# MIMXRT1062 register map
Vendor: nxp.com; File version: 1.0
CPU: CM7 r0p1, little endian, MPU, FPU, VTOR, 4 interrupt priority bits
Registers are 32-bit, read-write, reset 0x0 unless marked. A register's access mark holds for its fields unless they carry their own. Offsets are from the block's base; [hi:lo] are bit positions; {n}, {i} and the like mark numbered series; 'fields as' and 'values as' point back to an identical list.

## PMU
Base 0x400D8000; register names take the prefix PMU_; alternate view of CCM_ANALOG
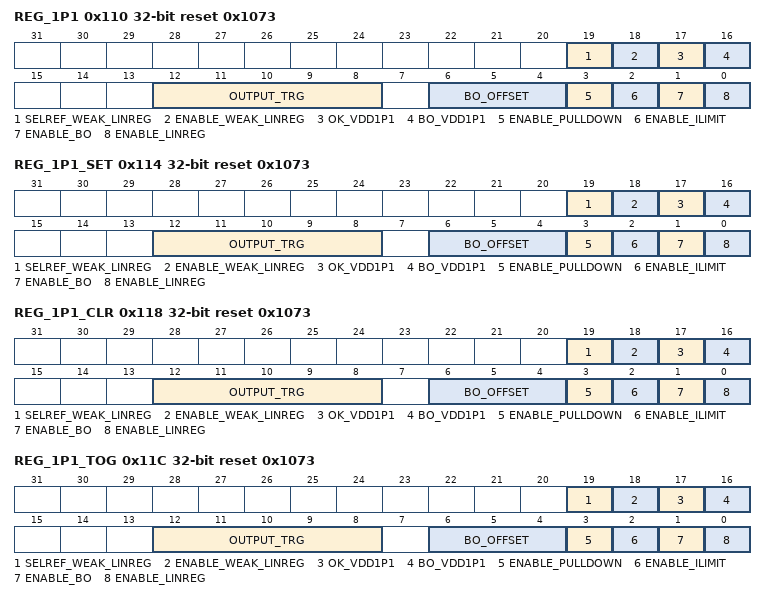
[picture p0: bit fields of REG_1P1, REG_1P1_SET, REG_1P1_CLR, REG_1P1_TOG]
0x110 REG_1P1 reset 0x1073 — Regulator 1P1 Register
  [19] SELREF_WEAK_LINREG — Selects the source for the reference voltage of the weak 1p1 regulator.
    0=Weak-linreg output tracks low-power-bandgap voltage; 1=Weak-linreg output tracks VDD_SOC_IN voltage
  [18] ENABLE_WEAK_LINREG — Enables the weak 1p1 regulator
  [17] OK_VDD1P1 ro — Status bit that signals when the regulator output is ok. 1 = regulator output > brownout target
  [16] BO_VDD1P1 ro — Status bit that signals when a brownout is detected on the regulator output.
  [12:8] OUTPUT_TRG — Control bits to adjust the regulator output voltage
    4=0.8V; 16=1.1V
  [6:4] BO_OFFSET — Control bits to adjust the regulator brownout offset voltage in 25mV steps
  [3] ENABLE_PULLDOWN — Control bit to enable the pull-down circuitry in the regulator
  [2] ENABLE_ILIMIT — Control bit to enable the current-limit circuitry in the regulator.
  [1] ENABLE_BO — Control bit to enable the brownout circuitry in the regulator.
  [0] ENABLE_LINREG — Control bit to enable the regulator output.
0x114 REG_1P1_SET reset 0x1073 — Regulator 1P1 Register
  fields as REG_1P1
0x118 REG_1P1_CLR reset 0x1073 — Regulator 1P1 Register
  fields as REG_1P1
0x11C REG_1P1_TOG reset 0x1073 — Regulator 1P1 Register
  fields as REG_1P1
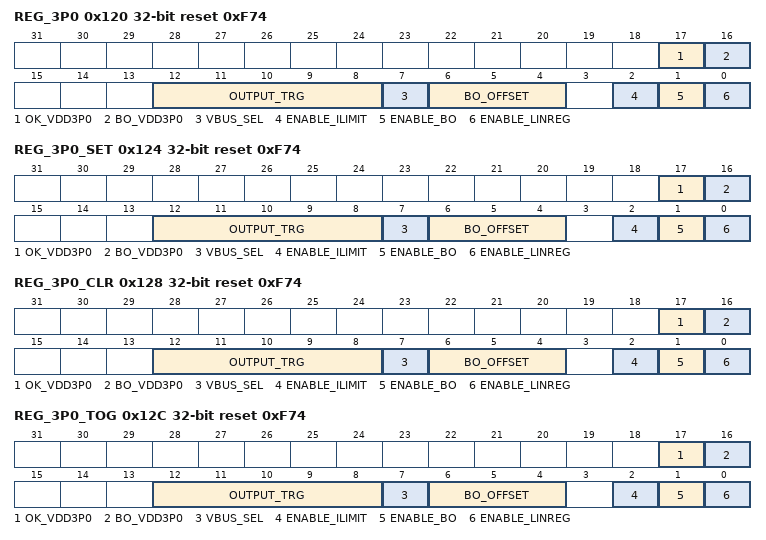
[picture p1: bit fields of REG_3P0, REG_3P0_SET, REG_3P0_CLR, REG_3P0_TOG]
0x120 REG_3P0 reset 0xF74 — Regulator 3P0 Register
  [17] OK_VDD3P0 ro — Status bit that signals when the regulator output is ok. 1 = regulator output > brownout target
  [16] BO_VDD3P0 ro — Status bit that signals when a brownout is detected on the regulator output.
  [12:8] OUTPUT_TRG — Control bits to adjust the regulator output voltage
    0=2.625V; 15=3.000V; 31=3.400V
  [7] VBUS_SEL — Select input voltage source for LDO_3P0 from either USB_OTG1_VBUS or USB_OTG2_VBUS
    0=USB_OTG2_VBUS (Utilize VBUS OTG2 power); 1=USB_OTG1_VBUS (Utilize VBUS OTG1 power)
  [6:4] BO_OFFSET — Control bits to adjust the regulator brownout offset voltage in 25mV steps
  [2] ENABLE_ILIMIT — Control bit to enable the current-limit circuitry in the regulator.
  [1] ENABLE_BO — Control bit to enable the brownout circuitry in the regulator.
  [0] ENABLE_LINREG — Control bit to enable the regulator output to be set by the programmed target voltage setting and internal bandgap reference
0x124 REG_3P0_SET reset 0xF74 — Regulator 3P0 Register
  fields as REG_3P0
0x128 REG_3P0_CLR reset 0xF74 — Regulator 3P0 Register
  fields as REG_3P0
0x12C REG_3P0_TOG reset 0xF74 — Regulator 3P0 Register
  fields as REG_3P0
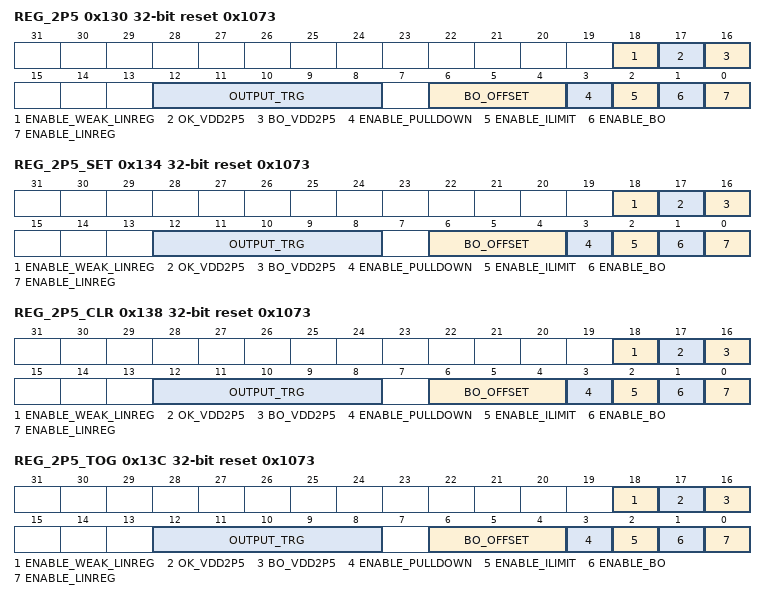
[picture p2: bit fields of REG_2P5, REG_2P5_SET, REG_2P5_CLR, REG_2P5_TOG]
0x130 REG_2P5 reset 0x1073 — Regulator 2P5 Register
  [18] ENABLE_WEAK_LINREG — Enables the weak 2p5 regulator
  [17] OK_VDD2P5 ro — Status bit that signals when the regulator output is ok. 1 = regulator output > brownout target
  [16] BO_VDD2P5 ro — Status bit that signals when a brownout is detected on the regulator output.
  [12:8] OUTPUT_TRG — Control bits to adjust the regulator output voltage
    0=2.10V; 16=2.50V; 31=2.875V
  [6:4] BO_OFFSET — Control bits to adjust the regulator brownout offset voltage in 25mV steps
  [3] ENABLE_PULLDOWN — Control bit to enable the pull-down circuitry in the regulator
  [2] ENABLE_ILIMIT — Control bit to enable the current-limit circuitry in the regulator.
  [1] ENABLE_BO — Control bit to enable the brownout circuitry in the regulator.
  [0] ENABLE_LINREG — Control bit to enable the regulator output.
0x134 REG_2P5_SET reset 0x1073 — Regulator 2P5 Register
  fields as REG_2P5
0x138 REG_2P5_CLR reset 0x1073 — Regulator 2P5 Register
  fields as REG_2P5
0x13C REG_2P5_TOG reset 0x1073 — Regulator 2P5 Register
  fields as REG_2P5
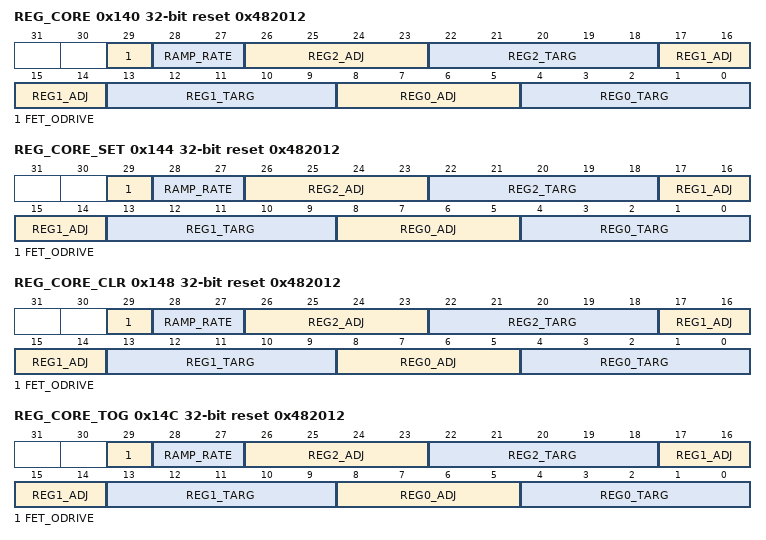
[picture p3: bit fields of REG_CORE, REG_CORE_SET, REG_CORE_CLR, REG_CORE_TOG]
0x140 REG_CORE reset 0x482012 — Digital Regulator Core Register
  [29] FET_ODRIVE — If set, increases the gate drive on power gating FETs to reduce leakage in the off state
  [28:27] RAMP_RATE — Regulator voltage ramp rate.
    0=Fast; 1=Medium Fast; 2=Medium Slow; 3=Slow
  [26:23] REG2_ADJ — This bit field defines the adjustment bits to calibrate the target value of Reg2. The adjustment is applied on top on any adjustment applied to the global reference in the misc0 register.
    0=No adjustment; 1=+ 0.25%; 2=+ 0.50%; 3=+ 0.75%; 4=+ 1.00%; 5=+ 1.25%; 6=+ 1.50%; 7=+ 1.75%; 8=- 0.25%; 9=- 0.50%; 10=- 0.75%; 11=- 1.00%; 12=- 1.25%; 13=- 1.50%; 14=- 1.75%; 15=- 2.00%
  [22:18] REG2_TARG — This field defines the target voltage for the SOC power domain
    0=Power gated off; 1=Target core voltage = 0.725V; 2=Target core voltage = 0.750V; 3=Target core voltage = 0.775V; 16=Target core voltage = 1.100V; 30=Target core voltage = 1.450V; 31=Power FET switched full on. No regulation.
  [17:14] REG1_ADJ — This bit field defines the adjustment bits to calibrate the target value of Reg1. The adjustment is applied on top on any adjustment applied to the global reference in the misc0 register.
    values as REG2_ADJ
  [13:9] REG1_TARG — This bit field defines the target voltage for the vpu/gpu power domain. Single bit increments reflect 25mV core voltage steps. Not all steps will make sense to use either because of input supply limitations or load operation.
    values as REG2_TARG
  [8:5] REG0_ADJ — This bit field defines the adjustment bits to calibrate the target value of Reg0. The adjustment is applied on top on any adjustment applied to the global reference in the misc0 register.
    values as REG2_ADJ
  [4:0] REG0_TARG — This field defines the target voltage for the Arm core power domain
    values as REG2_TARG
0x144 REG_CORE_SET reset 0x482012 — Digital Regulator Core Register
  fields as REG_CORE
0x148 REG_CORE_CLR reset 0x482012 — Digital Regulator Core Register
  fields as REG_CORE
0x14C REG_CORE_TOG reset 0x482012 — Digital Regulator Core Register
  fields as REG_CORE
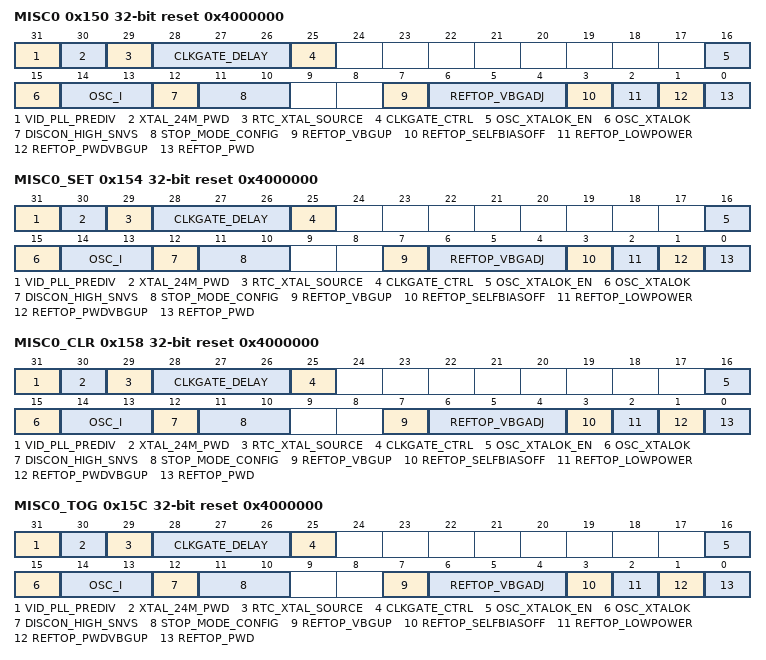
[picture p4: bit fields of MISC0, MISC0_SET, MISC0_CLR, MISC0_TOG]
0x150 MISC0 reset 0x4000000 — Miscellaneous Register 0
  [31] VID_PLL_PREDIV — Predivider for the source clock of the PLL's.
    0=Divide by 1; 1=Divide by 2
  [30] XTAL_24M_PWD — This field powers down the 24M crystal oscillator if set true.
  [29] RTC_XTAL_SOURCE ro — This field indicates which chip source is being used for the rtc clock.
    0=Internal ring oscillator; 1=RTC_XTAL
  [28:26] CLKGATE_DELAY — This field specifies the delay between powering up the XTAL 24MHz clock and releasing the clock to the digital logic inside the analog block
    0=0.5ms; 1=1.0ms; 2=2.0ms; 3=3.0ms; 4=4.0ms; 5=5.0ms; 6=6.0ms; 7=7.0ms
  [25] CLKGATE_CTRL — This bit allows disabling the clock gate (always ungated) for the xtal 24MHz clock that clocks the digital logic in the analog block
    0=ALLOW_AUTO_GATE (Allow the logic to automatically gate the clock when the XTAL is powered down.); 1=NO_AUTO_GATE (Prevent the logic from ever gating off the clock.)
  [16] OSC_XTALOK_EN — This bit enables the detector that signals when the 24MHz crystal oscillator is stable
  [15] OSC_XTALOK ro — Status bit that signals that the output of the 24-MHz crystal oscillator is stable
  [14:13] OSC_I — This field determines the bias current in the 24MHz oscillator
    0=NOMINAL; 1=MINUS_12_5_PERCENT (Decrease current by 12.5%); 2=MINUS_25_PERCENT (Decrease current by 25.0%); 3=MINUS_37_5_PERCENT (Decrease current by 37.5%)
  [12] DISCON_HIGH_SNVS — This bit controls a switch from VDD_HIGH_IN to VDD_SNVS_IN.
    0=Turn on the switch; 1=Turn off the switch
  [11:10] STOP_MODE_CONFIG — Configure the analog behavior in stop mode.
    0=SUSPEND (DSM); 1=STANDBY (Analog regulators are ON.); 2=STOP (lower power); 3=STOP (very lower power)
  [7] REFTOP_VBGUP — Status bit that signals the analog bandgap voltage is up and stable. 1 - Stable.
  [6:4] REFTOP_VBGADJ
    0=Nominal VBG; 1=VBG+0.78%; 2=VBG+1.56%; 3=VBG+2.34%; 4=VBG-0.78%; 5=VBG-1.56%; 6=VBG-2.34%; 7=VBG-3.12%
  [3] REFTOP_SELFBIASOFF — Control bit to disable the self-bias circuit in the analog bandgap
    0=Uses coarse bias currents for startup; 1=Uses bandgap-based bias currents for best performance
  [2] REFTOP_LOWPOWER — Control bit to enable the low-power mode in the analog bandgap.
  [1] REFTOP_PWDVBGUP — Control bit to power down the VBG-up detection circuitry in the analog bandgap.
  [0] REFTOP_PWD — Control bit to power-down the analog bandgap reference circuitry
0x154 MISC0_SET reset 0x4000000 — Miscellaneous Register 0
  fields as MISC0
0x158 MISC0_CLR reset 0x4000000 — Miscellaneous Register 0
  fields as MISC0
0x15C MISC0_TOG reset 0x4000000 — Miscellaneous Register 0
  fields as MISC0
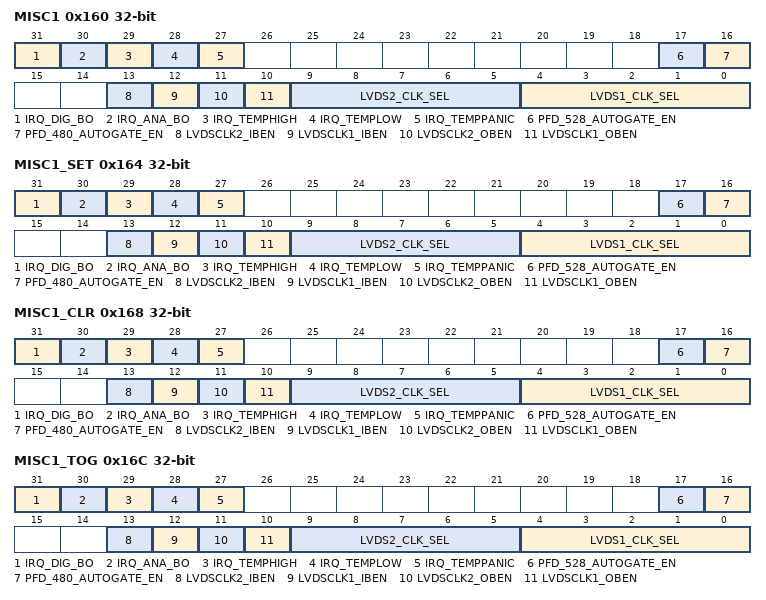
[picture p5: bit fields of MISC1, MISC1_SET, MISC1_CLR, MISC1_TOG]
0x160 MISC1 — Miscellaneous Register 1
  [31] IRQ_DIG_BO write-1-clears — This status bit is set to one when when any of the digital regulator brownout interrupts assert
  [30] IRQ_ANA_BO write-1-clears — This status bit is set to one when when any of the analog regulator brownout interrupts assert
  [29] IRQ_TEMPHIGH write-1-clears — This status bit is set to one when the temperature sensor high interrupt asserts for high temperature
  [28] IRQ_TEMPLOW write-1-clears — This status bit is set to one when the temperature sensor low interrupt asserts for low temperature
  [27] IRQ_TEMPPANIC write-1-clears — This status bit is set to one when the temperature sensor panic interrupt asserts for a panic high temperature
  [17] PFD_528_AUTOGATE_EN — This enables a feature that will clkgate (reset) all PFD_528 clocks anytime the PLL_528 is unlocked or powered off
  [16] PFD_480_AUTOGATE_EN — This enables a feature that will clkgate (reset) all PFD_480 clocks anytime the USB1_PLL_480 is unlocked or powered off
  [13] LVDSCLK2_IBEN — This enables the LVDS input buffer for anaclk2/2b
  [12] LVDSCLK1_IBEN — This enables the LVDS input buffer for anaclk1/1b
  [11] LVDSCLK2_OBEN — This enables the LVDS output buffer for anaclk2/2b
  [10] LVDSCLK1_OBEN — This enables the LVDS output buffer for anaclk1/1b
  [9:5] LVDS2_CLK_SEL — This field selects the clk to be routed to anaclk2/2b.Not related to PMU.
    0=ARM_PLL; 1=SYS_PLL (System PLL); {v}=PFD{v+2} (ref_pfd{v+2}_clk == pll2_pfd{v-2}_clk) (v=2..5); 6=AUDIO_PLL; 7=VIDEO_PLL; 8=MLB_PLL; 9=ETHERNET_REF (ethernet ref clock (ENET_PLL)); 10=PCIE_REF (PCIe ref clock (125M)); 11=SATA_REF (SATA ref clock (100M)); 12=USB1_PLL (USB1 PLL clock); 13=USB2_PLL (USB2 PLL clock); {v}=PFD{v-14} (ref_pfd{v-14}_clk == pll3_pfd{v-14}_clk) (v=14..17); 18=XTAL (xtal (24M)); 19=LVDS1 (LVDS1 (loopback)); 20=LVDS2 (LVDS2 (not useful))
  [4:0] LVDS1_CLK_SEL — This field selects the clk to be routed to anaclk1/1b.Not related to PMU.
    0=ARM_PLL; 1=SYS_PLL (System PLL); {v}=PFD{v+2} (ref_pfd{v+2}_clk == pll2_pfd{v-2}_clk) (v=2..5); 6=AUDIO_PLL; 7=VIDEO_PLL; 9=ETHERNET_REF (ethernet ref clock (ENET_PLL)); 12=USB1_PLL (USB1 PLL clock); 13=USB2_PLL (USB2 PLL clock); {v}=PFD{v-14} (ref_pfd{v-14}_clk == pll3_pfd{v-14}_clk) (v=14..17); 18=XTAL (xtal (24M))
0x164 MISC1_SET — Miscellaneous Register 1
  fields as MISC1
0x168 MISC1_CLR — Miscellaneous Register 1
  fields as MISC1
0x16C MISC1_TOG — Miscellaneous Register 1
  fields as MISC1
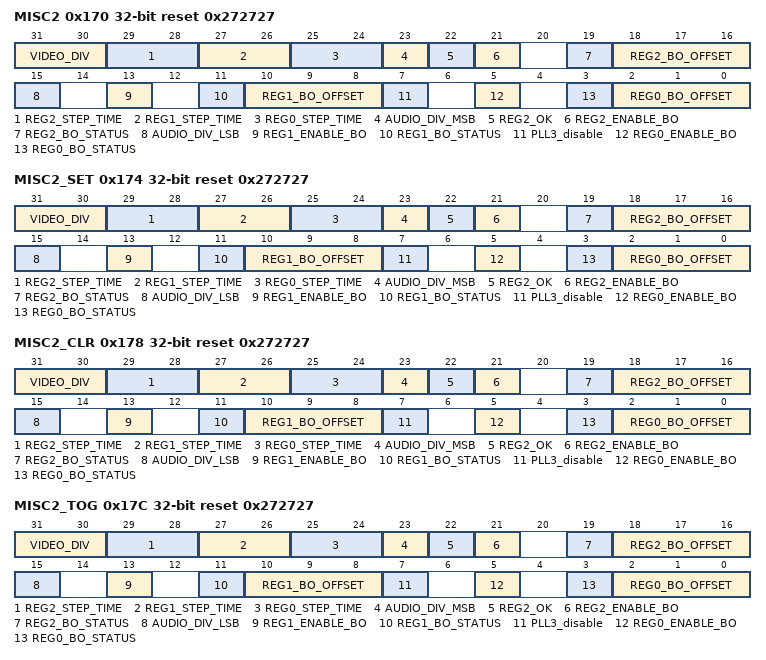
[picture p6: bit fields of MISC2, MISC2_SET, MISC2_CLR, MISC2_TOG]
0x170 MISC2 reset 0x272727 — Miscellaneous Control Register
  [31:30] VIDEO_DIV — Post-divider for video
    0=divide by 1 (Default); 1=divide by 2; 2=divide by 1; 3=divide by 4
  [29:28] REG2_STEP_TIME — Number of clock periods (24MHz clock).
    0=64_CLOCKS; 1=128_CLOCKS; 2=256_CLOCKS; 3=512_CLOCKS
  [27:26] REG1_STEP_TIME — Number of clock periods (24MHz clock).
    0=64_CLOCKS; 1=128_CLOCKS; 2=256_CLOCKS; 3=512_CLOCKS
  [25:24] REG0_STEP_TIME — Number of clock periods (24MHz clock).
    0=64_CLOCKS; 1=128_CLOCKS; 2=256_CLOCKS; 3=512_CLOCKS
  [23] AUDIO_DIV_MSB — MSB of Post-divider for Audio PLL
    0=divide by 1 (Default); 1=divide by 2
  [22] REG2_OK ro — Signals that the voltage is above the brownout level for the SOC supply
  [21] REG2_ENABLE_BO — Enables the brownout detection.
  [19] REG2_BO_STATUS ro — Reg2 brownout status bit.
  [18:16] REG2_BO_OFFSET ro — This field defines the brown out voltage offset for the xPU power domain
    4=Brownout offset = 0.100V; 7=Brownout offset = 0.175V
  [15] AUDIO_DIV_LSB — LSB of Post-divider for Audio PLL
    0=divide by 1 (Default); 1=divide by 2
  [13] REG1_ENABLE_BO — Enables the brownout detection.
  [11] REG1_BO_STATUS ro — Reg1 brownout status bit.
    1=Brownout, supply is below target minus brownout offset
  [10:8] REG1_BO_OFFSET ro — This field defines the brown out voltage offset for the xPU power domain
    4=Brownout offset = 0.100V; 7=Brownout offset = 0.175V
  [7] PLL3_disable — Default value of "0"
  [5] REG0_ENABLE_BO — Enables the brownout detection.
  [3] REG0_BO_STATUS ro — Reg0 brownout status bit.
    1=Brownout, supply is below target minus brownout offset
  [2:0] REG0_BO_OFFSET ro — This field defines the brown out voltage offset for the CORE power domain
    4=Brownout offset = 0.100V; 7=Brownout offset = 0.175V
0x174 MISC2_SET reset 0x272727 — Miscellaneous Control Register
  fields as MISC2
0x178 MISC2_CLR reset 0x272727 — Miscellaneous Control Register
  fields as MISC2
0x17C MISC2_TOG reset 0x272727 — Miscellaneous Control Register
  fields as MISC2

## Notices in the file
Copyright 2016-2022 NXP
All rights reserved.
SPDX-License-Identifier: BSD-3-Clause
